# ATmega16HVBrevB register map
Vendor: Atmel; File version: 1.0
CPU: other r0p0, little endian, no MPU, no FPU, 4 interrupt priority bits
Registers are 8-bit, read-write, reset 0x0 unless marked. A register's access mark holds for its fields unless they carry their own. Offsets are from the block's base; [hi:lo] are bit positions.

## BOOT_LOAD — Bootloader
Base 0x00800057
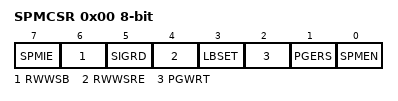
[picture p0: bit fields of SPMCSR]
0x00 SPMCSR — Store Program Memory Control and Status Register
  [7] SPMIE — SPM Interrupt Enable
  [6] RWWSB — Read-While-Write Section Busy
  [5] SIGRD — Signature Row Read
  [4] RWWSRE — Read-While-Write Section Read Enable
  [3] LBSET — Lock Bit Set
  [2] PGWRT — Page Write
  [1] PGERS — Page Erase
  [0] SPMEN — Store Program Memory Enable

## CELL_BALANCING
Base 0x008000F1
0x00 CBCR — Cell Balancing Control Register
  [3:0] CBE — Cell Balancing Enables

## CHARGER_DETECT
Base 0x008000D4
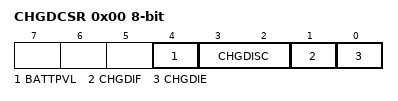
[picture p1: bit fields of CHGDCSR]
0x00 CHGDCSR — Charger Detect Control and Status Register
  [4] BATTPVL — BATT Pin Voltage Level
  [3:2] CHGDISC — Charger Detect Interrupt Sense Control
  [1] CHGDIF — Charger Detect Interrupt Flag
  [0] CHGDIE — Charger Detect Interrupt Enable

## COULOMB_COUNTER
Base 0x008000E0
0x00 CADAC0 — ADC Accumulate Current
  [7:0] CADAC0 — ADC accumulate current bits
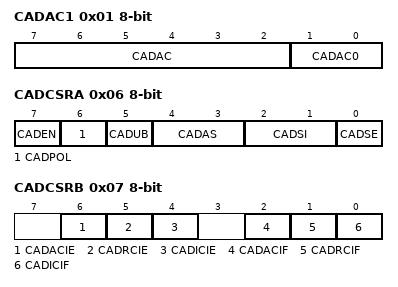
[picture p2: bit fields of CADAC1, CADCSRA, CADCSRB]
0x01 CADAC1 — ADC Accumulate Current
  [7:2] CADAC — ADC accumulate current bits
  [1:0] CADAC0 — ADC accumulate current bits
0x02 CADAC2 — ADC Accumulate Current
  [7:0] CADAC — ADC accumulate current bits
0x03 CADAC3 — ADC Accumulate Current
  [7:0] CADAC — ADC accumulate current bits
0x04 CADIC 16-bit (reset mask 0xFF) — CC-ADC Instantaneous Current
0x06 CADCSRA — CC-ADC Control and Status Register A
  [7] CADEN — When the CADEN bit is cleared (zero), the CC-ADC is disabled. When the CADEN bit is set (one), the CC-ADC will continuously measure the voltage drop over the external sense resistor RSENSE. In Power-down, only the Regular Current detection is active. In Power-off, the CC-ADC is always disabled.
  [6] CADPOL
  [5] CADUB — CC_ADC Update Busy
  [4:3] CADAS — CC_ADC Accumulate Current Select Bits
  [2:1] CADSI — The CADSI bits determine the current sampling interval for the Regular Current detection in Power-down mode. The actual settings remain to be determined.
  [0] CADSE — When the CADSE bit is written to one, the ongoing CC-ADC conversion is aborted, and the CC-ADC enters Regular Current detection mode.
0x07 CADCSRB — CC-ADC Control and Status Register B
  [6] CADACIE
  [5] CADRCIE — Regular Current Interrupt Enable
  [4] CADICIE — CAD Instantaneous Current Interrupt Enable
  [2] CADACIF — CC-ADC Accumulate Current Interrupt Flag
  [1] CADRCIF — CC-ADC Accumulate Current Interrupt Flag
  [0] CADICIF — CC-ADC Instantaneous Current Interrupt Flag
0x08 CADCSRC — CC-ADC Control and Status Register C
  [0] CADVSE — CC-ADC Voltage Scaling Enable
0x09 CADRCC — CC-ADC Regular Charge Current
0x0A CADRDC — CC-ADC Regular Discharge Current

## CPU — CPU Registers
Base 0x00800037
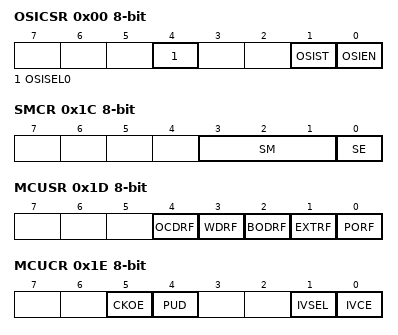
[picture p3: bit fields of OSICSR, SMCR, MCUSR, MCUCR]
0x00 OSICSR — Oscillator Sampling Interface Control and Status Register (read-only for debugger)
  [4] OSISEL0 — Oscillator Sampling Interface Select 0
  [1] OSIST — Oscillator Sampling Interface Status
  [0] OSIEN — Oscillator Sampling Interface Enable
0x07 GPIOR0 — General Purpose IO Register 0
  [7:0] GPIOR0 — General Purpose IO bits
0x13 GPIOR1 — General Purpose IO Register 1
  [7:0] GPIOR1 — General Purpose IO bits
0x14 GPIOR2 — General Purpose IO Register 2
  [7:0] GPIOR2 — General Purpose IO bits
0x1C SMCR — Sleep Mode Control Register
  [3:1] SM — Sleep Mode Select bits
    0=IDLE; 1=ADC; 3=PSAVE (Power Save); 4=POFF (Power Off)
  [0] SE — Sleep Enable
0x1D MCUSR — MCU Status Register (read-only for debugger)
  [4] OCDRF — OCD Reset Flag
  [3] WDRF — Watchdog Reset Flag
  [2] BODRF — Brown-out Reset Flag
  [1] EXTRF — External Reset Flag
  [0] PORF — Power-on reset flag
0x1E MCUCR — MCU Control Register
  [5] CKOE — Clock Output Enable
  [4] PUD — Pull-up disable
  [1] IVSEL — Interrupt Vector Select
  [0] IVCE — Interrupt Vector Change Enable
0x26 SP 16-bit (reset mask 0xFF) — Stack Pointer
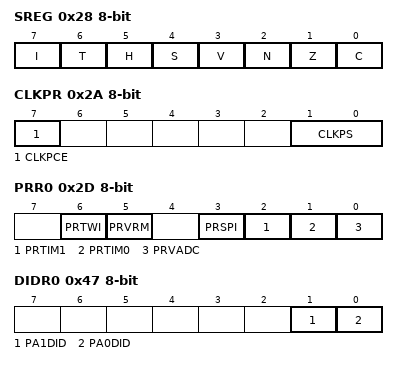
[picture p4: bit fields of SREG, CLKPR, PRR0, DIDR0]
0x28 SREG — Status Register
  [7] I — Global Interrupt Enable
  [6] T — Bit Copy Storage
  [5] H — Half Carry Flag
  [4] S — Sign Bit
  [3] V — Two's Complement Overflow Flag
  [2] N — Negative Flag
  [1] Z — Zero Flag
  [0] C — Carry Flag
0x2A CLKPR — Clock Prescale Register (read-only for debugger)
  [7] CLKPCE — Clock Prescaler Change Enable
  [1:0] CLKPS — Clock Prescaler Select Bits
0x2D PRR0 — Power Reduction Register 0
  [6] PRTWI — Power Reduction TWI
  [5] PRVRM — Power Reduction Voltage Regulator Monitor
  [3] PRSPI — Power reduction SPI
  [2] PRTIM1 — Power Reduction Timer/Counter1
  [1] PRTIM0 — Power Reduction Timer/Counter0
  [0] PRVADC — Power Reduction V-ADC
0x2F FOSCCAL — Fast Oscillator Calibration Value
  [7:0] FCAL
0x47 DIDR0 — Digital Input Disable Register
  [1] PA1DID — When this bit is written logic one, the digital input buffer of the corresponding V_ADC pin is disabled.
  [0] PA0DID — When this bit is written logic one, the digital input buffer of the corresponding V_ADC pin is disabled.
